# GD32F10x_CL register map
File version: 1.0
CPU: CM3 r2p1, little endian, no MPU, no FPU, 4 interrupt priority bits
Registers are 32-bit, read-write, reset 0x0 unless marked. A register's access mark holds for its fields unless they carry their own. Offsets are from the block's base; [hi:lo] are bit positions; {n}, {i} and the like mark numbered series; 'fields as' and 'values as' point back to an identical list.

## ENET_PTP — Ethernet: Precision time protocol
Base 0x40028700
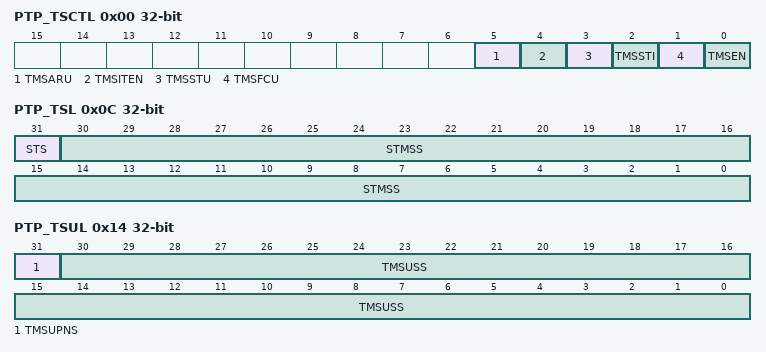
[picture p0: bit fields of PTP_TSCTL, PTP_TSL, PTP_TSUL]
0x00 PTP_TSCTL — Ethernet PTP time stamp control register (PTP_TSCTL)
  [5] TMSARU — Time stamp addend register update
  [4] TMSITEN — Time stamp interrupt trigger enable
  [3] TMSSTU — Time stamp system time update
  [2] TMSSTI — Time stamp system time initialize
  [1] TMSFCU — Time stamp fine or coarse update
  [0] TMSEN — Time stamp enable
0x04 PTP_SSINC — Ethernet PTP subsecond increment register
  [7:0] STMSSI — System time subsecond increment
0x08 PTP_TSH ro — Ethernet PTP time stamp high register
  [31:0] STMS — System time second
0x0C PTP_TSL ro — Ethernet PTP time stamp low register (PTP_TSL)
  [31] STS — System time sign
  [30:0] STMSS — System time subseconds
0x10 PTP_TSUH — Ethernet PTP time stamp high update register
  [31:0] TMSUS — Time stamp update second
0x14 PTP_TSUL — Ethernet PTP time stamp low update register (PTP_TSUL)
  [31] TMSUPNS — Time stamp update positive or negative sign
  [30:0] TMSUSS — Time stamp update subseconds
0x18 PTP_TSADDEND — Ethernet PTP time stamp addend register
  [31:0] TMSA — Time stamp addend
0x1C PTP_ETH — Ethernet PTP expected time high register
  [31:0] ETSH — Expected time stamp high
0x20 PTP_ETL — Ethernet PTP expected time low register
  [31:0] ETSL — Expected time stamp low

## ENET_MAC_FCTH — MAC flow control threshold register
Base 0x40029080
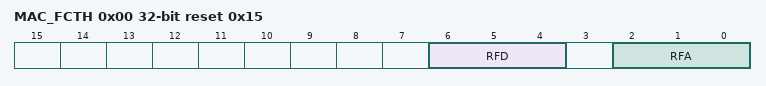
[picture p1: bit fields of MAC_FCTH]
0x00 MAC_FCTH reset 0x15 — Ethernet MAC flow control threshold register
  [6:4] RFD — Threshold of deactive flow control
  [2:0] RFA — Threshold of active flow control

## EXTI — External interrupt/event controller
Base 0x40010400
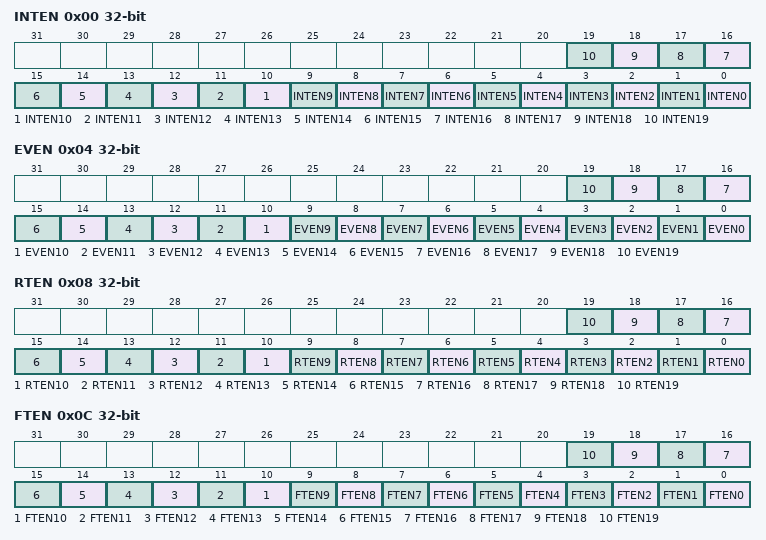
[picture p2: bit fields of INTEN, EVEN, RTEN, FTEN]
0x00 INTEN — Interrupt enable register (EXTI_INTEN)
  [n] INTEN{n} (n=0..19) — Enable Interrupt on line {n}
0x04 EVEN — Event enable register (EXTI_EVEN)
  [n] EVEN{n} (n=0..19) — Enable Event on line {n}
0x08 RTEN — Rising Edge Trigger Enable register (EXTI_RTEN)
  [n] RTEN{n} (n=0..19) — Rising edge trigger enable of line {n}
0x0C FTEN — Falling Egde Trigger Enable register (EXTI_FTEN)
  [n] FTEN{n} (n=0..19) — Falling edge trigger enable of line {n}
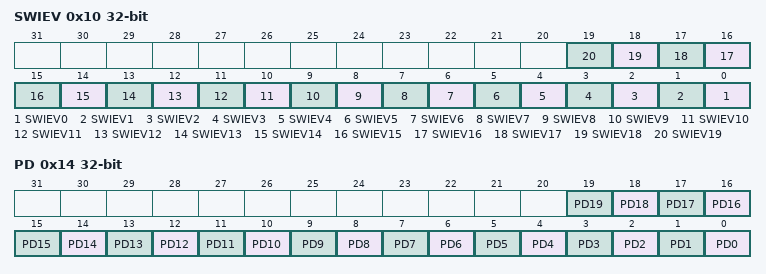
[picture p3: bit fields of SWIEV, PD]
0x10 SWIEV — Software interrupt event register (EXTI_SWIEV)
  [n] SWIEV{n} (n=0..19) — Interrupt/Event software trigger on line {n}
0x14 PD — Pending register (EXTI_PD)
  [n] PD{n} (n=0..19) — Interrupt pending status of line {n}

## FMC
Base 0x40022000
0x00 WS — wait state counter register
  [2:0] WSCNT
0x04 KEY0 wo — Unlock key register 0
  [31:0] KEY — FMC_CTL0 unlock key
0x08 OBKEY wo — Option byte unlock key register
  [31:0] OBKEY — FMC_ CTL0 option byte operation unlock register
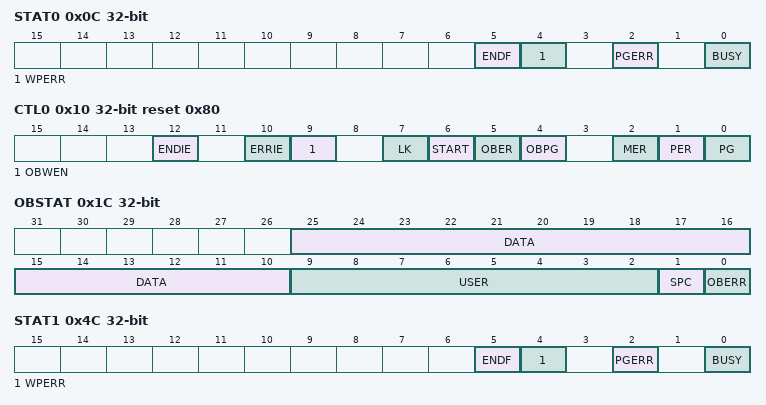
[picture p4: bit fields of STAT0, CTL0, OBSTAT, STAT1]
0x0C STAT0 access per field — Status register 0
  [5] ENDF rw — End of operation flag bit
  [4] WPERR rw — Erase/Program protection error flag bit
  [2] PGERR rw — Program error flag bit
  [0] BUSY ro — The flash is busy bit
0x10 CTL0 reset 0x80 — Control register 0
  [12] ENDIE — End of operation interrupt enable bit
  [10] ERRIE — Error interrupt enable bit
  [9] OBWEN — Option byte erase/program enable bit
  [7] LK — FMC_CTL0 lock bit
  [6] START — Send erase command to FMC bit
  [5] OBER — Option bytes erase command bit
  [4] OBPG — Option bytes program command bit
  [2] MER — Main flash mass erase for bank0 command bit
  [1] PER — Main flash page erase for bank0 command bit
  [0] PG — Main flash program for bank0 command bit
0x14 ADDR0 wo — Address register 0
  [31:0] ADDR — Flash erase/program command address bits
0x1C OBSTAT ro — Option byte status register
  [25:10] DATA — Store DATA[15:0] of option bytes block after system reset
  [9:2] USER — Store USER of option bytes block after system reset
  [1] SPC — Option bytes security protection code
  [0] OBERR — Option bytes read error bit
0x20 WP ro — Erase/Program Protection register
  [31:0] WP — Store WP[31:0] of option bytes block after system reset
0x44 KEY1 wo — Unlock key register 1
  [31:0] KEY — FMC_CTL1 unlock register
0x4C STAT1 access per field — Status register 1
  fields as STAT0
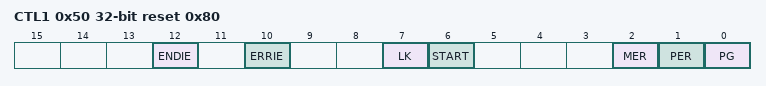
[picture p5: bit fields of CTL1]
0x50 CTL1 reset 0x80 — Control register 1
  [12] ENDIE — End of operation interrupt enable bit
  [10] ERRIE — Error interrupt enable bit
  [7] LK — FMC_CTL1 lock bit
  [6] START — Send erase command to FMC bit
  [2] MER — Main flash mass erase for bank1 command bit
  [1] PER — Main flash page erase for bank1 command bit
  [0] PG — Main flash program for bank1 command bit
0x54 ADDR1 wo — Address register 1
  [31:0] ADDR — Flash erase/program command address bits
0xFC WSEN — Wait state enable register
  [0] WSEN — FMC wait state enable register
0x100 PID ro — Product ID register
  [31:0] PID — Product reserved ID code register
